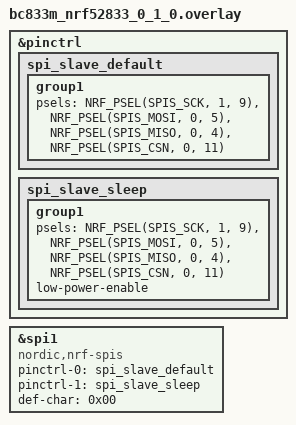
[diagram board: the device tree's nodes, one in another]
&pinctrl {
	spi_slave_default: spi_slave_default {
		group1 {
			psels = <NRF_PSEL(SPIS_SCK, 1, 9)>,
					<NRF_PSEL(SPIS_MOSI, 0, 5)>,
					<NRF_PSEL(SPIS_MISO, 0, 4)>,
					<NRF_PSEL(SPIS_CSN, 0, 11)>;
		};
	};

	spi_slave_sleep: spi_slave_sleep {
		group1 {
			psels = <NRF_PSEL(SPIS_SCK, 1, 9)>,
					<NRF_PSEL(SPIS_MOSI, 0, 5)>,
					<NRF_PSEL(SPIS_MISO, 0, 4)>,
					<NRF_PSEL(SPIS_CSN, 0, 11)>;
			low-power-enable;
		};
	};
};

my_spi_slave: &spi1 {
	compatible = "nordic,nrf-spis";
	status = "okay";
	pinctrl-0 = <&spi_slave_default>;
	pinctrl-1 = <&spi_slave_sleep>;
	pinctrl-names = "default", "sleep";
	def-char = <0x00>;
};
